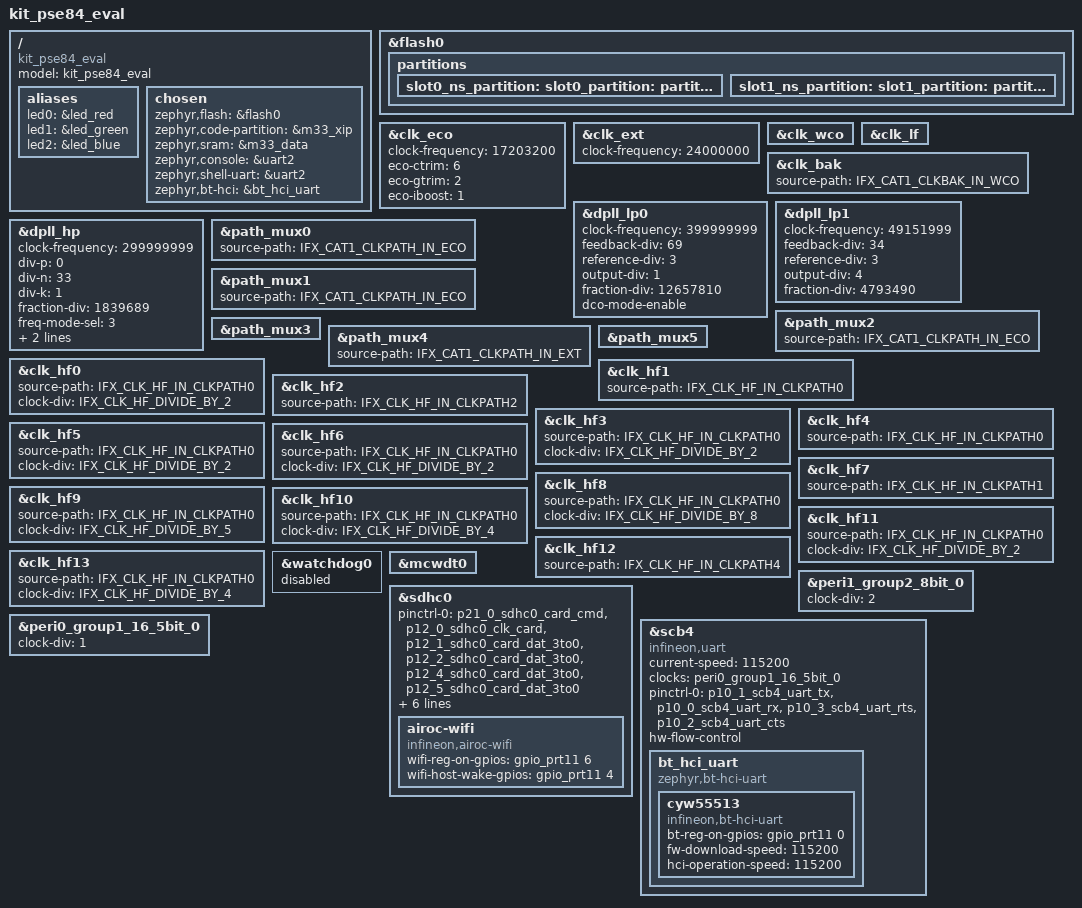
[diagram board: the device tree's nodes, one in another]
/*
 * SPDX-FileCopyrightText: Copyright (c) 2026 Infineon Technologies AG,
 * SPDX-FileCopyrightText: or an affiliate of Infineon Technologies AG. All rights reserved.
 *
 * SPDX-License-Identifier: Apache-2.0
 */

/dts-v1/;
#include <infineon/edge/mpns/pse846gps2dbzc4a.dtsi>
#include <infineon/edge/pse84/pse84.cm33.dtsi>
#include <infineon/edge/pse84/system_clocks.dtsi>

#include "kit_pse84_eval_common.dtsi"
#include "kit_pse84_eval_memory_map.dtsi"

#include <zephyr/dt-bindings/input/input-event-codes.h>

/ {
	model = "kit_pse84_eval";
	compatible = "kit_pse84_eval";

	aliases {
		led0 = &led_red;
		led1 = &led_green;
		led2 = &led_blue;
	};

	chosen {
		zephyr,flash = &flash0;
		zephyr,code-partition = &m33_xip;
		zephyr,sram = &m33_data;
		zephyr,console = &uart2;
		zephyr,shell-uart = &uart2;
		zephyr,bt-hci = &bt_hci_uart;
	};
};

/*
 * Bind the relative MCUboot slot0_partition/slot1_partition labels to
 * the Non-Secure image slots so the stock cmake/mcuboot.cmake signing
 * script sizes the Non-Secure image against its own slot (0x1c0000)
 * rather than the Secure slot.
 *
 * The slot0_ns_partition/slot1_ns_partition labels are attached here too
 * (rather than in the shared memory map) because only the Non-Secure
 * build consumes them: Zephyr's TF-M integration looks them up by name
 * (dt_nodelabel ... REQUIRED) to size the Non-Secure image, and the DFU /
 * mcumgr image-management subsystems reference them at run time.
 */
&flash0 {
	partitions {
		slot0_ns_partition: slot0_partition: partition@340000 {};

		slot1_ns_partition: slot1_partition: partition@940000 {};
	};
};

/*
 * System clocks. On this target they are configured by TF-M at boot, which
 * builds its clock setup from the nodes below.
 */

&clk_eco {
	status = "okay";
	clock-frequency = <17203200>;
	eco-ctrim = <6>;
	eco-gtrim = <2>;
	eco-iboost = <1>;
};

&clk_ext {
	status = "okay";
	clock-frequency = <24000000>;
};

&clk_wco {
	status = "okay";
};

&clk_lf {
	status = "okay";
};

&clk_bak {
	status = "okay";
	source-path = <IFX_CAT1_CLKBAK_IN_WCO>;
};

/* clock path 0: 17.2032 MHz * (69 + 12657810 / 2^24) / 3 / 1 */
&dpll_lp0 {
	status = "okay";
	clock-frequency = <399999999>;
	feedback-div = <69>;
	reference-div = <3>;
	output-div = <1>;
	fraction-div = <12657810>;
	dco-mode-enable;
};

/* clock path 1: 17.2032 MHz * (34 + 4793490 / 2^24) / 3 / 4 */
&dpll_lp1 {
	status = "okay";
	clock-frequency = <49151999>;
	feedback-div = <34>;
	reference-div = <3>;
	output-div = <4>;
	fraction-div = <4793490>;
};

/* clock path 2: 17.2032 MHz * (33 + 1 + 1839689 / 2^21) / (0 + 1) / (1 + 1) */
&dpll_hp {
	status = "okay";
	clock-frequency = <299999999>;
	div-p = <0>;
	div-n = <33>;
	div-k = <1>;
	fraction-div = <1839689>;
	freq-mode-sel = <3>;
	flock-enable-threshold = <7>;
	lf-beta-value = <16>;
};

&path_mux0 {
	status = "okay";
	source-path = <IFX_CAT1_CLKPATH_IN_ECO>;
};

&path_mux1 {
	status = "okay";
	source-path = <IFX_CAT1_CLKPATH_IN_ECO>;
};

&path_mux2 {
	status = "okay";
	source-path = <IFX_CAT1_CLKPATH_IN_ECO>;
};

&path_mux3 {
	status = "okay";
};

&path_mux4 {
	status = "okay";
	source-path = <IFX_CAT1_CLKPATH_IN_EXT>;
};

&path_mux5 {
	status = "okay";
};

&clk_hf0 {
	status = "okay";
	source-path = <IFX_CLK_HF_IN_CLKPATH0>;
	clock-div = <IFX_CLK_HF_DIVIDE_BY_2>;
};

&clk_hf1 {
	status = "okay";
	source-path = <IFX_CLK_HF_IN_CLKPATH0>;
};

&clk_hf2 {
	status = "okay";
	source-path = <IFX_CLK_HF_IN_CLKPATH2>;
};

&clk_hf3 {
	status = "okay";
	source-path = <IFX_CLK_HF_IN_CLKPATH0>;
	clock-div = <IFX_CLK_HF_DIVIDE_BY_2>;
};

&clk_hf4 {
	status = "okay";
	source-path = <IFX_CLK_HF_IN_CLKPATH0>;
};

&clk_hf5 {
	status = "okay";
	source-path = <IFX_CLK_HF_IN_CLKPATH0>;
	clock-div = <IFX_CLK_HF_DIVIDE_BY_2>;
};

&clk_hf6 {
	status = "okay";
	source-path = <IFX_CLK_HF_IN_CLKPATH0>;
	clock-div = <IFX_CLK_HF_DIVIDE_BY_2>;
};

&clk_hf7 {
	status = "okay";
	source-path = <IFX_CLK_HF_IN_CLKPATH1>;
};

&clk_hf8 {
	status = "okay";
	source-path = <IFX_CLK_HF_IN_CLKPATH0>;
	clock-div = <IFX_CLK_HF_DIVIDE_BY_8>;
};

&clk_hf9 {
	status = "okay";
	source-path = <IFX_CLK_HF_IN_CLKPATH0>;
	clock-div = <IFX_CLK_HF_DIVIDE_BY_5>;
};

&clk_hf10 {
	status = "okay";
	source-path = <IFX_CLK_HF_IN_CLKPATH0>;
	clock-div = <IFX_CLK_HF_DIVIDE_BY_4>;
};

&clk_hf11 {
	status = "okay";
	source-path = <IFX_CLK_HF_IN_CLKPATH0>;
	clock-div = <IFX_CLK_HF_DIVIDE_BY_2>;
};

&clk_hf12 {
	status = "okay";
	source-path = <IFX_CLK_HF_IN_CLKPATH4>;
};

&clk_hf13 {
	status = "okay";
	source-path = <IFX_CLK_HF_IN_CLKPATH0>;
	clock-div = <IFX_CLK_HF_DIVIDE_BY_4>;
};

/* watchdog0 is a secure-owned resource; disable it in the non-secure build. */
&watchdog0 {
	status = "disabled";
};

&mcwdt0 {
	status = "okay";
};

&peri1_group2_8bit_0 {
	status = "okay";
	clock-div = <2>;
};

&sdhc0 {
	status = "okay";

	/* SDIO pins */
	pinctrl-0 = <&p21_0_sdhc0_card_cmd &p12_0_sdhc0_clk_card &p12_1_sdhc0_card_dat_3to0
		     &p12_2_sdhc0_card_dat_3to0 &p12_4_sdhc0_card_dat_3to0
		     &p12_5_sdhc0_card_dat_3to0>;
	pinctrl-names = "default";

	clocks = <&peri1_group2_8bit_0>;
	bus-width = <4>;
	max-bus-freq = <50000000>;
	min-bus-freq = <400000>;
	power-delay-ms = <1000>;
	no-1-8-v;

	/* Wi-Fi configuration */
	airoc-wifi {
		status = "okay";
		compatible = "infineon,airoc-wifi";

		/* Wi-Fi control gpios */
		wifi-reg-on-gpios = <&gpio_prt11 6 GPIO_ACTIVE_HIGH>;
		wifi-host-wake-gpios = <&gpio_prt11 4 GPIO_ACTIVE_HIGH>;
	};
};

&peri0_group1_16_5bit_0 {
	status = "okay";
	clock-div = <1>;
};

uart4: &scb4 {
	compatible = "infineon,uart";
	status = "okay";

	current-speed = <115200>;

	clocks = <&peri0_group1_16_5bit_0>;

	/* HCI-UART pins */
	pinctrl-0 = <&p10_1_scb4_uart_tx &p10_0_scb4_uart_rx &p10_3_scb4_uart_rts
		     &p10_2_scb4_uart_cts>;
	pinctrl-names = "default";

	/* HW Flow control must be enabled for HCI H4 */
	hw-flow-control;

	bt_hci_uart: bt_hci_uart {
		compatible = "zephyr,bt-hci-uart";

		cyw55513 {
			status = "okay";
			compatible = "infineon,bt-hci-uart";
			bt-reg-on-gpios = <&gpio_prt11 0 GPIO_ACTIVE_HIGH>;
			fw-download-speed = <115200>;
			hci-operation-speed = <115200>;
		};
	};
};
